# STM32F070xB register map
File version: 1.0
Registers are 32-bit, read-write, reset 0x0 unless marked. A register's access mark holds for its fields unless they carry their own. Offsets are from the block's base; [hi:lo] are bit positions; {n}, {i} and the like mark numbered series; 'fields as' and 'values as' point back to an identical list.

## ADC
Base 0x40012708
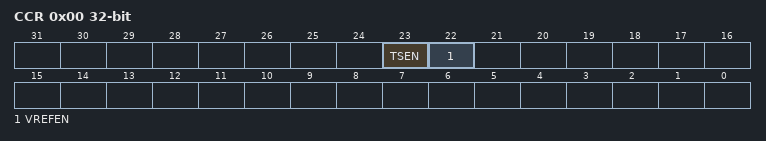
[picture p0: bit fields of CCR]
0x00 CCR — ADC common configuration register
  [23] TSEN — ADC internal path to temperature sensor enable
  [22] VREFEN — ADC internal path to VrefInt enable

## DBGMCU — Debug MCU
Base 0x40015800
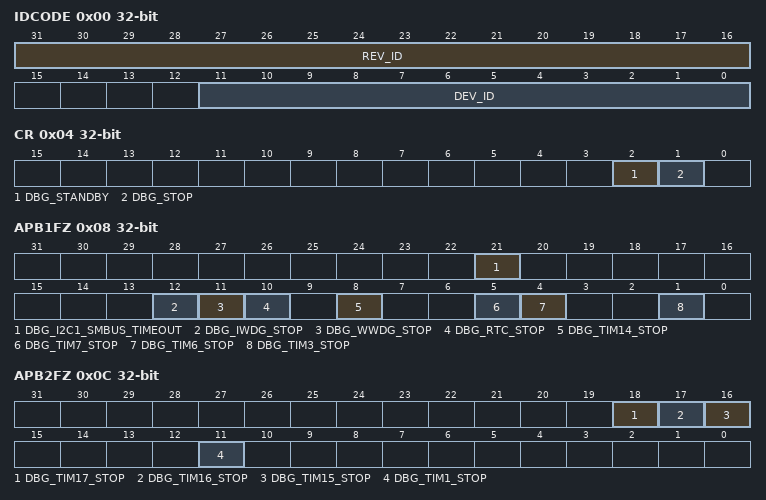
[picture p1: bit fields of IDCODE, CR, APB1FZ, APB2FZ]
0x00 IDCODE — MCU device ID code
  [31:16] REV_ID — REV_ID[15:0] bits (Revision Identifier)
  [11:0] DEV_ID — Device Identifier
0x04 CR — Debug MCU configuration register
  [2] DBG_STANDBY — Debug Standby mode
  [1] DBG_STOP — Debug Stop Mode
0x08 APB1FZ — Debug MCU APB1 freeze register
  [21] DBG_I2C1_SMBUS_TIMEOUT — I2C1 SMBUS timeout mode stopped when Core is halted
  [12] DBG_IWDG_STOP — Debug Independent Watchdog stopped when Core is halted
  [11] DBG_WWDG_STOP — Debug Window Watchdog stopped when Core is halted
  [10] DBG_RTC_STOP — RTC Calendar frozen when core is halted
  [8] DBG_TIM14_STOP — TIM14 counter stopped when core is halted
  [5] DBG_TIM7_STOP — TIM7 counter stopped when core is halted
  [4] DBG_TIM6_STOP — TIM6 counter stopped when core is halted
  [1] DBG_TIM3_STOP — TIM3 counter stopped when core is halted
0x0C APB2FZ — Debug MCU APB2 freeze register
  [18] DBG_TIM17_STOP — TIM17 counter stopped when core is halted
  [17] DBG_TIM16_STOP — TIM16 counter stopped when core is halted
  [16] DBG_TIM15_STOP — TIM15 counter stopped when core is halted
  [11] DBG_TIM1_STOP — TIM1 counter stopped when core is halted

## DMA1
Base 0x40020000
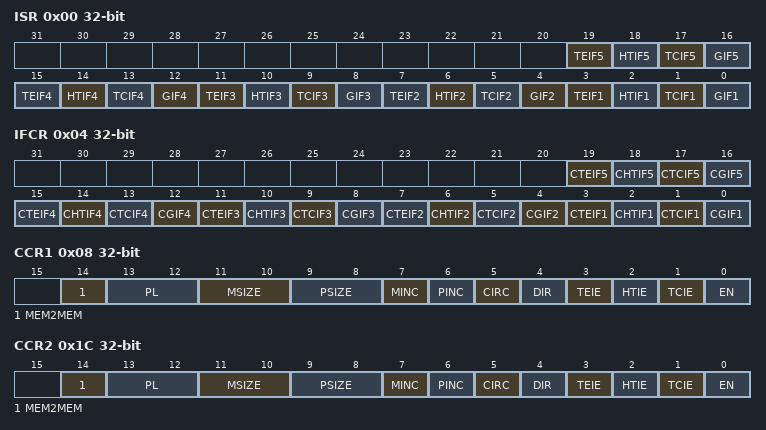
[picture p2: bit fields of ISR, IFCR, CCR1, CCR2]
0x00 ISR — DMA interrupt status register
  [4n-1] TEIF{n} (n=1..5) — Channel {n} Transfer Error flag
  [4n-2] HTIF{n} (n=1..5) — Channel {n} Half Transfer flag
  [4n-3] TCIF{n} (n=1..5) — Channel {n} Transfer Complete flag
  [4n-4] GIF{n} (n=1..5) — Channel {n} Global interrupt flag
0x04 IFCR — DMA interrupt flag clear register
  [4n-1] CTEIF{n} (n=1..5) — Channel {n} Transfer Error clear
  [4n-2] CHTIF{n} (n=1..5) — Channel {n} Half Transfer clear
  [4n-3] CTCIF{n} (n=1..5) — Channel {n} Transfer Complete clear
  [4n-4] CGIF{n} (n=1..5) — Channel {n} Global interrupt clear
0x08 CCR1 — DMA channel x configuration register
  [14] MEM2MEM — Memory to memory mode
  [13:12] PL — PL[1:0] bits(Channel Priority level)
  [11:10] MSIZE — MSIZE[1:0] bits (Memory size)
  [9:8] PSIZE — PSIZE[1:0] bits (Peripheral size)
  [7] MINC — Memory increment mode
  [6] PINC — Peripheral increment mode
  [5] CIRC — Circular mode
  [4] DIR — Data transfer direction
  [3] TEIE — Transfer error interrupt enable
  [2] HTIE — Half Transfer interrupt enable
  [1] TCIE — Transfer complete interrupt enable
  [0] EN — Channel enable
0x0C CNDTR1 — DMA channel x number of data register
  [15:0] NDT — Number of data to Transfer
0x10 CPAR1 — DMA channel x peripheral address register
  [31:0] PA — Peripheral Address
{0x0+0x14*i} CMAR{i} (i=1..5) — DMA channel x memory address register
  [31:0] MA — Memory Address
0x1C CCR2 — DMA channel x configuration register
  fields as CCR1
0x20 CNDTR2 — DMA channel x number of data register
  [15:0] NDT — Number of data to Transfer
0x24 CPAR2 — DMA channel x peripheral address register
  [31:0] PA — Peripheral Address
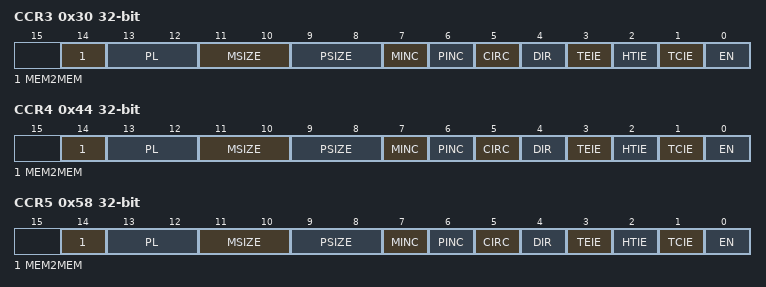
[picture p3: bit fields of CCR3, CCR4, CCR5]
0x30 CCR3 — DMA channel x configuration register
  fields as CCR1
0x34 CNDTR3 — DMA channel x number of data register
  [15:0] NDT — Number of data to Transfer
0x38 CPAR3 — DMA channel x peripheral address register
  [31:0] PA — Peripheral Address
0x44 CCR4 — DMA channel x configuration register
  fields as CCR1
0x48 CNDTR4 — DMA channel x number of data register
  [15:0] NDT — Number of data to Transfer
0x4C CPAR4 — DMA channel x peripheral address register
  [31:0] PA — Peripheral Address
0x58 CCR5 — DMA channel x configuration register
  fields as CCR1
0x5C CNDTR5 — DMA channel x number of data register
  [15:0] NDT — Number of data to Transfer
0x60 CPAR5 — DMA channel x peripheral address register
  [31:0] PA — Peripheral Address

## FLASH — FLASH Registers
Base 0x40022000
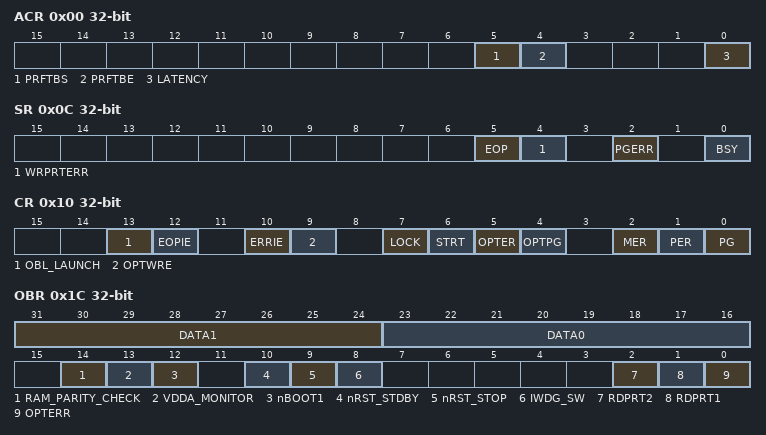
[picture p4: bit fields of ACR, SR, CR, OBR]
0x00 ACR — FLASH access control register
  [5] PRFTBS — Prefetch Buffer Status
  [4] PRFTBE — Prefetch Buffer Enable
  [0] LATENCY — LATENCY bit (Latency)
    0=FLASH Zero Latency cycle; 1=FLASH One Latency cycle
0x04 KEYR — FLASH key register
  [31:0] FKEYR — FPEC Key
0x08 OPTKEYR — FLASH OPT key register
  [31:0] OPTKEYR — Option Byte Key
0x0C SR — FLASH status register
  [5] EOP — End of operation
  [4] WRPRTERR — Write Protection Error
  [2] PGERR — Programming Error
  [0] BSY — Busy
0x10 CR — FLASH control register
  [13] OBL_LAUNCH — Option Bytes Loader Launch
  [12] EOPIE — End of operation interrupt enable
  [10] ERRIE — Error Interrupt Enable
  [9] OPTWRE — Option Bytes Write Enable
  [7] LOCK
  [6] STRT — Start
  [5] OPTER — Option Byte Erase
  [4] OPTPG — Option Byte Programming
  [2] MER — Mass Erase
  [1] PER — Page Erase
  [0] PG — Programming
0x14 AR — FLASH address register
  [31:0] FAR — Flash Address
0x1C OBR — FLASH option bytes register
  [31:24] DATA1
  [23:16] DATA0
  [14] RAM_PARITY_CHECK
  [13] VDDA_MONITOR — VDDA power supply supervisor
  [12] nBOOT1
  [10] nRST_STDBY
  [9] nRST_STOP
  [8] IWDG_SW
  [2] RDPRT2 — Read protection Level 2
  [1] RDPRT1 — Read protection Level 1
  [0] OPTERR — Option Byte Error
0x20 WRPR — FLASH option bytes register
  [15:0] WRP — Write Protect

## CRC — CRC calculation unit
Base 0x40023000
0x00 DR — CRC Data register
  [31:0] DR — Data register bits
0x04 IDR 8-bit — CRC Independent data register
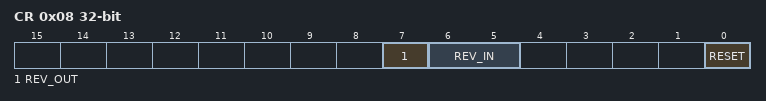
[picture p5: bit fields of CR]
0x08 CR — CRC Control register
  [7] REV_OUT — REV_OUT Reverse Output Data bits
    0=NONE (Output Data bit order not affected); 1=BIT (Output Data bit reversal done by bit)
  [6:5] REV_IN — REV_IN Reverse Input Data bits
    0=NONE (Input Data bit order not affected); 1=BYTE (Input Data bit reversal done by byte); 2=HALFWORD (Input Data bit reversal done by half-word); 3=WORD (Input Data bit reversal done by word)
  [0] RESET — RESET the CRC computation unit bit
0x10 INIT — Initial CRC value register
  [31:0] INIT — Initial CRC value bits

## GPIOA — General Purpose I/O
Base 0x48000000
Same registers: GPIOB 0x48000400, GPIOC 0x48000800, GPIOD 0x48000C00, GPIOF 0x48001400
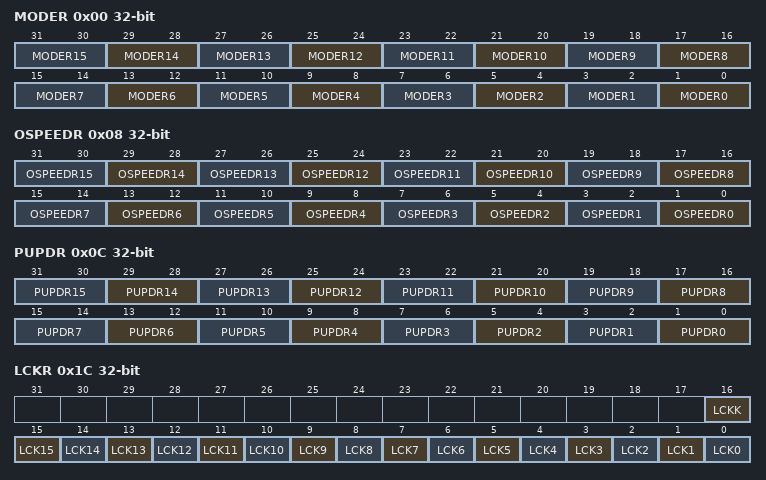
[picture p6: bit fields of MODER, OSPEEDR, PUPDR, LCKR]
0x00 MODER — GPIO port mode register
  [2n+1:2n] MODER{n} (n=0..15)
0x04 OTYPER — GPIO port output type register
0x08 OSPEEDR — GPIO port output speed register
  [2n+1:2n] OSPEEDR{n} (n=0..15)
0x0C PUPDR — GPIO port pull-up/pull-down register
  [2n+1:2n] PUPDR{n} (n=0..15)
0x10 IDR — GPIO port input data register
0x14 ODR — GPIO port output data register
0x18 BSRR — GPIO port bit set/reset register
0x1C LCKR — GPIO port configuration lock register
  [16] LCKK, [n] LCK{n} (n=0..15)
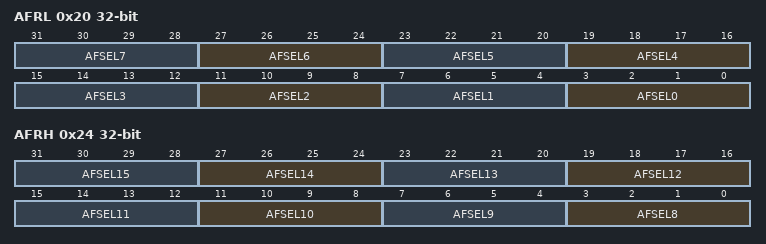
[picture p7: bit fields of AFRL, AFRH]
0x20 AFRL — GPIO alternate function low register
  [4n+3:4n] AFSEL{n} (n=0..7)
0x24 AFRH — GPIO alternate function low register
  [4n-29:4n-32] AFSEL{n} (n=8..15)
0x28 BRR — GPIO bit reset register
